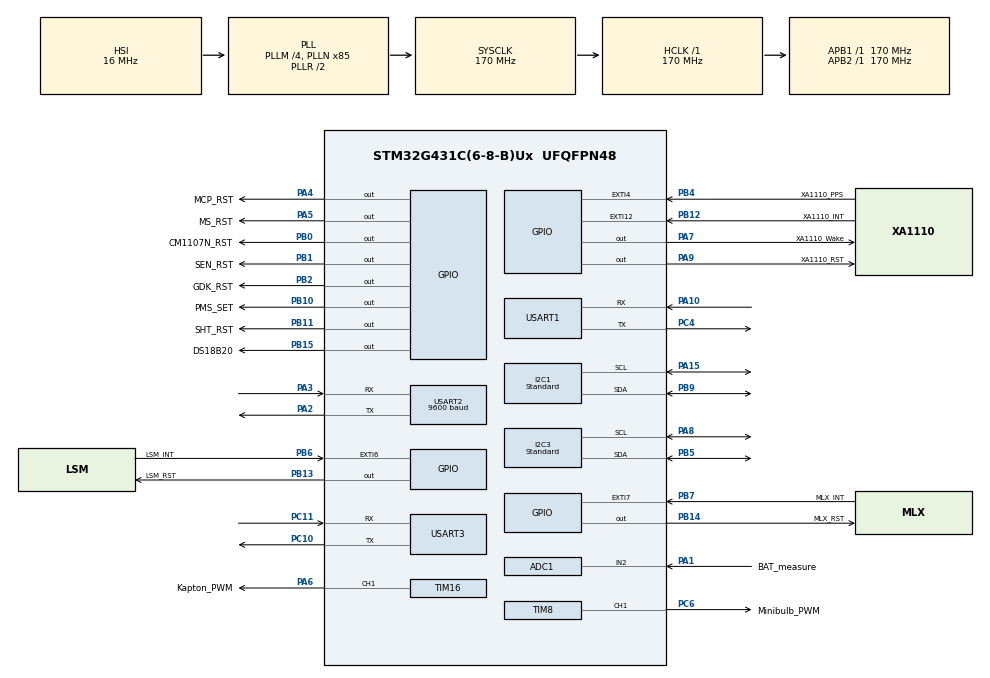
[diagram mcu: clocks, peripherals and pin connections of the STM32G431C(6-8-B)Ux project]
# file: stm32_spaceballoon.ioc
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ADC1.Channel-0\#ChannelRegularConversion=ADC_CHANNEL_2
ADC1.NbrOfConversion=1
ADC1.NbrOfConversionFlag=1
ADC1.OffsetNumber-0\#ChannelRegularConversion=ADC_OFFSET_NONE
ADC1.Rank-0\#ChannelRegularConversion=1
ADC1.SamplingTime-0\#ChannelRegularConversion=ADC_SAMPLETIME_2CYCLES_5
ADC1.master=1
Dma.ADC1.1.Direction=DMA_PERIPH_TO_MEMORY
Dma.ADC1.1.EventEnable=DISABLE
Dma.ADC1.1.Instance=DMA1_Channel2
Dma.ADC1.1.MemDataAlignment=DMA_MDATAALIGN_HALFWORD
Dma.ADC1.1.MemInc=DMA_MINC_ENABLE
Dma.ADC1.1.Mode=DMA_CIRCULAR
Dma.ADC1.1.PeriphDataAlignment=DMA_PDATAALIGN_HALFWORD
Dma.ADC1.1.PeriphInc=DMA_PINC_DISABLE
Dma.ADC1.1.Polarity=HAL_DMAMUX_REQ_GEN_RISING
Dma.ADC1.1.Priority=DMA_PRIORITY_MEDIUM
Dma.ADC1.1.RequestNumber=1
Dma.ADC1.1.SignalID=NONE
Dma.ADC1.1.SyncEnable=DISABLE
Dma.ADC1.1.SyncPolarity=HAL_DMAMUX_SYNC_NO_EVENT
Dma.ADC1.1.SyncRequestNumber=1
Dma.ADC1.1.SyncSignalID=NONE
Dma.Request0=USART1_RX
Dma.Request1=ADC1
Dma.Request2=USART2_RX
Dma.Request3=USART3_TX
Dma.USART1_RX.0.Direction=DMA_PERIPH_TO_MEMORY
Dma.USART1_RX.0.EventEnable=DISABLE
Dma.USART1_RX.0.Instance=DMA1_Channel1
Dma.USART1_RX.0.MemDataAlignment=DMA_MDATAALIGN_BYTE
Dma.USART1_RX.0.MemInc=DMA_MINC_ENABLE
Dma.USART1_RX.0.Mode=DMA_CIRCULAR
Dma.USART1_RX.0.PeriphDataAlignment=DMA_PDATAALIGN_BYTE
Dma.USART1_RX.0.PeriphInc=DMA_PINC_DISABLE
Dma.USART1_RX.0.Polarity=HAL_DMAMUX_REQ_GEN_RISING
Dma.USART1_RX.0.Priority=DMA_PRIORITY_HIGH
Dma.USART1_RX.0.RequestNumber=1
Dma.USART1_RX.0.SignalID=NONE
Dma.USART1_RX.0.SyncEnable=DISABLE
Dma.USART1_RX.0.SyncPolarity=HAL_DMAMUX_SYNC_NO_EVENT
Dma.USART1_RX.0.SyncRequestNumber=1
Dma.USART1_RX.0.SyncSignalID=NONE
Dma.USART2_RX.2.Direction=DMA_PERIPH_TO_MEMORY
Dma.USART2_RX.2.EventEnable=DISABLE
Dma.USART2_RX.2.Instance=DMA1_Channel3
Dma.USART2_RX.2.MemDataAlignment=DMA_MDATAALIGN_BYTE
Dma.USART2_RX.2.MemInc=DMA_MINC_ENABLE
Dma.USART2_RX.2.Mode=DMA_CIRCULAR
Dma.USART2_RX.2.PeriphDataAlignment=DMA_PDATAALIGN_BYTE
Dma.USART2_RX.2.PeriphInc=DMA_PINC_DISABLE
Dma.USART2_RX.2.Polarity=HAL_DMAMUX_REQ_GEN_RISING
Dma.USART2_RX.2.Priority=DMA_PRIORITY_MEDIUM
Dma.USART2_RX.2.RequestNumber=1
Dma.USART2_RX.2.SignalID=NONE
Dma.USART2_RX.2.SyncEnable=DISABLE
Dma.USART2_RX.2.SyncPolarity=HAL_DMAMUX_SYNC_NO_EVENT
Dma.USART2_RX.2.SyncRequestNumber=1
Dma.USART2_RX.2.SyncSignalID=NONE
Dma.USART3_TX.3.Direction=DMA_MEMORY_TO_PERIPH
Dma.USART3_TX.3.EventEnable=DISABLE
Dma.USART3_TX.3.Instance=DMA1_Channel4
Dma.USART3_TX.3.MemDataAlignment=DMA_MDATAALIGN_BYTE
Dma.USART3_TX.3.MemInc=DMA_MINC_ENABLE
Dma.USART3_TX.3.Mode=DMA_NORMAL
Dma.USART3_TX.3.PeriphDataAlignment=DMA_PDATAALIGN_BYTE
Dma.USART3_TX.3.PeriphInc=DMA_PINC_DISABLE
Dma.USART3_TX.3.Polarity=HAL_DMAMUX_REQ_GEN_RISING
Dma.USART3_TX.3.Priority=DMA_PRIORITY_LOW
Dma.USART3_TX.3.RequestNumber=1
Dma.USART3_TX.3.SignalID=NONE
Dma.USART3_TX.3.SyncEnable=DISABLE
Dma.USART3_TX.3.SyncPolarity=HAL_DMAMUX_SYNC_NO_EVENT
Dma.USART3_TX.3.SyncRequestNumber=1
Dma.USART3_TX.3.SyncSignalID=NONE
I2C1.AddressingMode=I2C_ADDRESSINGMODE_7BIT
I2C1.CustomTiming=Disabled
I2C1.I2C_Coeff_DF=4
I2C1.I2C_Speed_Mode=I2C_Standard
I2C1.Timing=0x50916FA0
I2C3.I2C_Coeff_DF=4
I2C3.I2C_Speed_Mode=I2C_Standard
I2C3.Timing=0x50916FA0
Mcu.Family=STM32G4
Mcu.Name=STM32G431C(6-8-B)Ux
Mcu.Package=UFQFPN48
NVIC.DMA1_Channel1_IRQn=true\:0\:0\:false\:false\:true\:false\:true\:true
NVIC.DMA1_Channel2_IRQn=true\:0\:0\:false\:false\:true\:false\:true\:true
NVIC.DMA1_Channel3_IRQn=true\:0\:0\:false\:false\:true\:false\:true\:true
NVIC.DMA1_Channel4_IRQn=true\:0\:0\:false\:false\:true\:false\:true\:true
NVIC.EXTI15_10_IRQn=true\:0\:0\:false\:false\:true\:false\:false\:false
NVIC.EXTI4_IRQn=true\:0\:0\:false\:false\:true\:false\:false\:false
NVIC.EXTI9_5_IRQn=true\:0\:0\:false\:false\:true\:false\:false\:false
NVIC.I2C1_ER_IRQn=true\:0\:0\:false\:false\:true\:true\:true\:true
NVIC.I2C1_EV_IRQn=true\:0\:0\:false\:false\:true\:true\:true\:true
NVIC.I2C3_ER_IRQn=true\:0\:0\:false\:false\:true\:true\:true\:true
NVIC.I2C3_EV_IRQn=true\:0\:0\:false\:false\:true\:true\:true\:true
NVIC.PVD_PVM_IRQn=true\:0\:0\:false\:false\:true\:true\:true\:true
NVIC.PriorityGroup=NVIC_PRIORITYGROUP_4
NVIC.TIM3_IRQn=true\:15\:0\:false\:false\:true\:false\:true\:true
NVIC.TimeBase=TIM3_IRQn
NVIC.TimeBaseIP=TIM3
NVIC.USART1_IRQn=true\:0\:0\:false\:false\:true\:true\:true\:true
NVIC.USART2_IRQn=true\:7\:0\:true\:false\:true\:true\:true\:true
NVIC.USART3_IRQn=true\:6\:0\:true\:false\:true\:true\:true\:true
PA1.GPIO_Label=BAT_measure
PA1.Mode=IN2-Single-Ended
PA1.Signal=ADC1_IN2
PA10.Mode=Asynchronous
PA10.Signal=USART1_RX
PA13.Mode=Serial_Wire
PA13.Signal=SYS_JTMS-SWDIO
PA14.Mode=Serial_Wire
PA14.Signal=SYS_JTCK-SWCLK
PA15.Mode=I2C
PA15.Signal=I2C1_SCL
PA2.Mode=Asynchronous
PA2.Signal=USART2_TX
PA3.Mode=Asynchronous
PA3.Signal=USART2_RX
PA4.GPIO_Label=MCP_RST
PA4.Signal=GPIO_Output
PA5.GPIO_Label=MS_RST
PA5.Signal=GPIO_Output
PA6.GPIO_Label=Kapton_PWM
PA6.Signal=S_TIM16_CH1
PA7.GPIO_Label=XA1110_Wake
PA7.Signal=GPIO_Output
PA8.Mode=I2C
PA8.Signal=I2C3_SCL
PA9.GPIO_Label=XA1110_RST
PA9.Signal=GPIO_Output
PB0.GPIO_Label=CM1107N_RST
PB0.Signal=GPIO_Output
PB1.GPIO_Label=SEN_RST
PB1.Signal=GPIO_Output
PB10.GPIO_Label=PMS_SET
PB10.Signal=GPIO_Output
PB11.GPIO_Label=SHT_RST
PB11.Signal=GPIO_Output
PB12.GPIO_Label=XA1110_INT
PB12.Signal=GPXTI12
PB13.GPIO_Label=LSM_RST
PB13.Signal=GPIO_Output
PB14.GPIO_Label=MLX_RST
PB14.Signal=GPIO_Output
PB15.GPIO_Label=DS18B20
PB15.GPIO_ModeDefaultOutputPP=GPIO_MODE_OUTPUT_OD
PB15.GPIO_PuPd=GPIO_NOPULL
PB15.Signal=GPIO_Output
PB2.GPIO_Label=GDK_RST
PB2.Signal=GPIO_Output
PB4.GPIO_Label=XA1110_PPS
PB4.Signal=GPXTI4
PB5.Mode=I2C
PB5.Signal=I2C3_SDA
PB6.GPIO_Label=LSM_INT
PB6.Signal=GPXTI6
PB7.GPIO_Label=MLX_INT
PB7.Signal=GPXTI7
PB9.Mode=I2C
PB9.Signal=I2C1_SDA
PC10.Mode=Asynchronous
PC10.Signal=USART3_TX
PC11.Mode=Asynchronous
PC11.Signal=USART3_RX
PC4.Mode=Asynchronous
PC4.Signal=USART1_TX
PC6.GPIO_Label=Minibulb_PWM
PC6.Signal=S_TIM8_CH1
ProjectManager.HeapSize=0x1000
ProjectManager.StackSize=0x1000
ProjectManager.TargetToolchain=STM32CubeIDE
RCC.ADC12Freq_Value=170000000
RCC.AHBFreq_Value=170000000
RCC.APB1Freq_Value=170000000
RCC.APB1TimFreq_Value=170000000
RCC.APB2Freq_Value=170000000
RCC.APB2TimFreq_Value=170000000
RCC.CortexFreq_Value=170000000
RCC.EXTERNAL_CLOCK_VALUE=12288000
RCC.HCLKFreq_Value=170000000
RCC.HSE_VALUE=8000000
RCC.HSI48_VALUE=48000000
RCC.HSI_VALUE=16000000
RCC.LSE_VALUE=32768
RCC.PLLM=RCC_PLLM_DIV4
RCC.PLLN=85
RCC.PREFETCH_ENABLE=1
RCC.SYSCLKFreq_VALUE=170000000
RCC.SYSCLKSource=RCC_SYSCLKSOURCE_PLLCLK
RCC.USBFreq_Value=170000000
RCC.VCOOutputFreq_Value=340000000
RTC.Date=3
RTC.Format=RTC_FORMAT_BIN
RTC.Hours=18
RTC.WeekDay=RTC_WEEKDAY_SATURDAY
RTC.Year=26
SH.S_TIM16_CH1.0=TIM16_CH1,PWM Generation1 CH1
SH.S_TIM8_CH1.0=TIM8_CH1,PWM Generation1 CH1
SYS.PVDLevel=PWR_PVDLEVEL_6
TIM16.Channel=TIM_CHANNEL_1
TIM16.PeriodNoDither=999
TIM16.Prescaler=169
TIM8.Channel-PWM\ Generation1\ CH1=TIM_CHANNEL_1
TIM8.PeriodNoDither=999
TIM8.Prescaler=169
USART1.VirtualMode-Asynchronous=VM_ASYNC
USART2.BaudRate=9600
USART2.Mode=MODE_TX_RX
USART2.VirtualMode-Asynchronous=VM_ASYNC
USART3.VirtualMode-Asynchronous=VM_ASYNC
VP_ADC1_Vbat_Input.Mode=IN-Vbat
VP_IWDG_VS_IWDG.Mode=IWDG_Activate
VP_RTC_VS_RTC_Activate.Mode=RTC_Enabled
VP_RTC_VS_RTC_Calendar.Mode=RTC_Calendar
VP_RTC_VS_RTC_WakeUp_intern.Mode=WakeUp
VP_SYS_VS_DBSignals.Mode=DisableDeadBatterySignals
VP_SYS_VS_tim3.Mode=TIM3
VP_SYS_V_PVD_IN.Mode=Mode_PVD_Int
VP_TIM16_VS_ClockSourceINT.Mode=Enable_Timer
VP_TIM1_VS_OPM.Mode=OPM_bit
VP_TIM8_VS_ClockSourceINT.Mode=Internal
VP_TIM8_VS_ClockSourceITR.Mode=TriggerSource_ITR0
VP_TIM8_VS_NoETR.Mode=ETR_as_clearing_source_through_remap_TIM8
board=custom

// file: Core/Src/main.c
/* USER CODE BEGIN Header */
/**
  ******************************************************************************
  * @file           : main.c
  * @brief          : Main program body
  ******************************************************************************
  */
/* USER CODE END Header */
#include "main.h"
#include "adc.h"
#include "dma.h"
#include "i2c.h"
#include "iwdg.h"
#include "rtc.h"
#include "tim.h"
#include "usart.h"
#include "gpio.h"

/* USER CODE BEGIN Includes */
#include <stdio.h> // For mock printf/data if needed
#include "app.h"
/* USER CODE END Includes */

void SystemClock_Config(void);

int main(void)
{

  /* MCU Configuration--------------------------------------------------------*/

  /* Reset of all peripherals, Initializes the Flash interface and the Systick. */
  HAL_Init();

  /* Configure the system clock */
  SystemClock_Config();

  /* Initialize all configured peripherals */
  MX_GPIO_Init();
  MX_DMA_Init();
  MX_I2C1_Init();
  MX_I2C3_Init();
  MX_TIM1_Init();
  MX_TIM8_Init();
  MX_TIM16_Init();
  MX_USART1_UART_Init();
  MX_USART2_UART_Init();
  MX_USART3_UART_Init();
  MX_RTC_Init();
  MX_ADC1_Init();
  MX_IWDG_Init();
  /* USER CODE BEGIN 2 */
  App_Init();
  /* USER CODE END 2 */

  /* Infinite loop */
  /* USER CODE BEGIN WHILE */
  while (1)
  {
      // Simple loop governor
      // In real OS/RTOS, this would be a task or timer callback
      App_Loop();

      // Delay to simulate 20ms (Very rough)
      // HAL_Delay(20);
    /* USER CODE END WHILE */

  }
}

void SystemClock_Config(void)
{
  RCC_OscInitTypeDef RCC_OscInitStruct = {0};
  RCC_ClkInitTypeDef RCC_ClkInitStruct = {0};

  /** Configure the main internal regulator output voltage
  */
  HAL_PWREx_ControlVoltageScaling(PWR_REGULATOR_VOLTAGE_SCALE1_BOOST);

  /** Initializes the RCC Oscillators according to the specified parameters
  * in the RCC_OscInitTypeDef structure.
  */
  RCC_OscInitStruct.OscillatorType = RCC_OSCILLATORTYPE_HSI|RCC_OSCILLATORTYPE_LSI;
  RCC_OscInitStruct.HSIState = RCC_HSI_ON;
  RCC_OscInitStruct.HSICalibrationValue = RCC_HSICALIBRATION_DEFAULT;
  RCC_OscInitStruct.LSIState = RCC_LSI_ON;
  RCC_OscInitStruct.PLL.PLLState = RCC_PLL_ON;
  RCC_OscInitStruct.PLL.PLLSource = RCC_PLLSOURCE_HSI;
  RCC_OscInitStruct.PLL.PLLM = RCC_PLLM_DIV4;
  RCC_OscInitStruct.PLL.PLLN = 85;
  RCC_OscInitStruct.PLL.PLLP = RCC_PLLP_DIV2;
  RCC_OscInitStruct.PLL.PLLQ = RCC_PLLQ_DIV2;
  RCC_OscInitStruct.PLL.PLLR = RCC_PLLR_DIV2;
  if (HAL_RCC_OscConfig(&RCC_OscInitStruct) != HAL_OK)
  {
    Error_Handler();
  }

  /** Initializes the CPU, AHB and APB buses clocks
  */
  RCC_ClkInitStruct.ClockType = RCC_CLOCKTYPE_HCLK|RCC_CLOCKTYPE_SYSCLK
                              |RCC_CLOCKTYPE_PCLK1|RCC_CLOCKTYPE_PCLK2;
  RCC_ClkInitStruct.SYSCLKSource = RCC_SYSCLKSOURCE_PLLCLK;
  RCC_ClkInitStruct.AHBCLKDivider = RCC_SYSCLK_DIV1;
  RCC_ClkInitStruct.APB1CLKDivider = RCC_HCLK_DIV1;
  RCC_ClkInitStruct.APB2CLKDivider = RCC_HCLK_DIV1;

  if (HAL_RCC_ClockConfig(&RCC_ClkInitStruct, FLASH_LATENCY_4) != HAL_OK)
  {
    Error_Handler();
  }
}

void HAL_TIM_PeriodElapsedCallback(TIM_HandleTypeDef *htim)
{
  if (htim->Instance == TIM3) {
    HAL_IncTick();
  }
}

void Error_Handler(void)
{
  __disable_irq();
  while (1)
  {
  }
}
